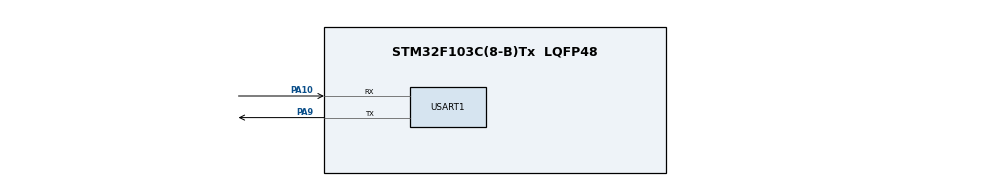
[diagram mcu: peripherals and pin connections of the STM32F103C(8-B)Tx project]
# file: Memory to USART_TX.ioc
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Dma.Request0=USART1_TX
Dma.USART1_TX.0.Direction=DMA_MEMORY_TO_PERIPH
Dma.USART1_TX.0.Instance=DMA1_Channel4
Dma.USART1_TX.0.MemDataAlignment=DMA_MDATAALIGN_BYTE
Dma.USART1_TX.0.MemInc=DMA_MINC_ENABLE
Dma.USART1_TX.0.Mode=DMA_NORMAL
Dma.USART1_TX.0.PeriphDataAlignment=DMA_PDATAALIGN_BYTE
Dma.USART1_TX.0.PeriphInc=DMA_PINC_DISABLE
Dma.USART1_TX.0.Priority=DMA_PRIORITY_HIGH
Mcu.Family=STM32F1
Mcu.Name=STM32F103C(8-B)Tx
Mcu.Package=LQFP48
NVIC.DMA1_Channel4_IRQn=true\:0\:0\:false\:false\:true\:false\:true
NVIC.PriorityGroup=NVIC_PRIORITYGROUP_4
PA10.Mode=Asynchronous
PA10.Signal=USART1_RX
PA13.Mode=Serial_Wire
PA13.Signal=SYS_JTMS-SWDIO
PA14.Mode=Serial_Wire
PA14.Signal=SYS_JTCK-SWCLK
PA9.Mode=Asynchronous
PA9.Signal=USART1_TX
PD0-OSC_IN.Mode=HSE-External-Oscillator
PD0-OSC_IN.Signal=RCC_OSC_IN
PD1-OSC_OUT.Mode=HSE-External-Oscillator
PD1-OSC_OUT.Signal=RCC_OSC_OUT
ProjectManager.HeapSize=0x200
ProjectManager.StackSize=0x400
ProjectManager.TargetToolchain=MDK-ARM V5.27
RCC.APB1Freq_Value=8000000
RCC.APB2Freq_Value=8000000
USART1.VirtualMode=VM_ASYNC
board=custom

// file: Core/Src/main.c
/* USER CODE BEGIN Header */
/**
  ******************************************************************************
  * @file           : main.c
  * @brief          : Main program body
  ******************************************************************************
  * @attention
  *
  * <h2><center>&copy; Copyright (c) 2021 STMicroelectronics.
  * All rights reserved.</center></h2>
  *
  * This software component is licensed by ST under BSD 3-Clause license,
  * the "License"; You may not use this file except in compliance with the
  * License. You may obtain a copy of the License at:
  *                        opensource.org/licenses/BSD-3-Clause
  *
  ******************************************************************************
  */
/* USER CODE END Header */
#include "main.h"

void SystemClock_Config(void);
static void MX_GPIO_Init(void);
static void MX_DMA_Init(void);
static void MX_USART1_UART_Init(void);

int main(void)
{
  /* USER CODE BEGIN 1 */
uint8_t message1[] = "\r\n Hey! This is a test message\r\n";		//Creating a buffer for the message that is to be sent to USART_TX
uint8_t ARRAYSIZE = sizeof(message1);								//Get the size of the buffer
  /* USER CODE END 1 */

  /* MCU Configuration--------------------------------------------------------*/

  /* Reset of all peripherals, Initializes the Flash interface and the Systick. */

  LL_APB2_GRP1_EnableClock(LL_APB2_GRP1_PERIPH_AFIO);
  LL_APB1_GRP1_EnableClock(LL_APB1_GRP1_PERIPH_PWR);

  NVIC_SetPriorityGrouping(NVIC_PRIORITYGROUP_4);

  /* System interrupt init*/

  /** NOJTAG: JTAG-DP Disabled and SW-DP Enabled
  */
  LL_GPIO_AF_Remap_SWJ_NOJTAG();

  /* Configure the system clock */
  SystemClock_Config();

  /* Initialize all configured peripherals */
  MX_GPIO_Init();
  MX_DMA_Init();
  MX_USART1_UART_Init();
  /* USER CODE BEGIN 2 */

	/* configure DMA channel 4 */

  LL_DMA_ConfigAddresses(DMA1,
                         LL_DMA_CHANNEL_4,
                         (uint32_t)message1,
						 LL_USART_DMA_GetRegAddr(USART1),				//Address of the first element of the memory buffer
                         LL_DMA_DIRECTION_MEMORY_TO_PERIPH);

	LL_DMA_SetDataLength(DMA1,
                       LL_DMA_CHANNEL_4,
											 ARRAYSIZE);

    LL_DMA_EnableChannel(DMA1,
                       LL_DMA_CHANNEL_4);

    LL_USART_EnableDMAReq_TX(USART1);									//Enable DMA request
  /* USER CODE END 2 */

  /* Infinite loop */
  while (1)
  {

  }
}

void SystemClock_Config(void)
{
  LL_FLASH_SetLatency(LL_FLASH_LATENCY_0);
  while(LL_FLASH_GetLatency()!= LL_FLASH_LATENCY_0)
  {
  }
  LL_RCC_HSI_SetCalibTrimming(16);
  LL_RCC_HSI_Enable();

   /* Wait till HSI is ready */
  while(LL_RCC_HSI_IsReady() != 1)
  {

  }
  LL_RCC_SetAHBPrescaler(LL_RCC_SYSCLK_DIV_1);
  LL_RCC_SetAPB1Prescaler(LL_RCC_APB1_DIV_1);
  LL_RCC_SetAPB2Prescaler(LL_RCC_APB2_DIV_1);
  LL_RCC_SetSysClkSource(LL_RCC_SYS_CLKSOURCE_HSI);

   /* Wait till System clock is ready */
  while(LL_RCC_GetSysClkSource() != LL_RCC_SYS_CLKSOURCE_STATUS_HSI)
  {

  }
  LL_Init1msTick(8000000);
  LL_SetSystemCoreClock(8000000);
}

static void MX_USART1_UART_Init(void)
{

  LL_USART_InitTypeDef USART_InitStruct = {0};

  LL_GPIO_InitTypeDef GPIO_InitStruct = {0};

  /* Peripheral clock enable */
  LL_APB2_GRP1_EnableClock(LL_APB2_GRP1_PERIPH_USART1);

  LL_APB2_GRP1_EnableClock(LL_APB2_GRP1_PERIPH_GPIOA);
  /**USART1 GPIO Configuration
  PA9   ------> USART1_TX
  PA10   ------> USART1_RX
  */
  GPIO_InitStruct.Pin = LL_GPIO_PIN_9;
  GPIO_InitStruct.Mode = LL_GPIO_MODE_ALTERNATE;
  GPIO_InitStruct.Speed = LL_GPIO_SPEED_FREQ_HIGH;
  GPIO_InitStruct.OutputType = LL_GPIO_OUTPUT_PUSHPULL;
  LL_GPIO_Init(GPIOA, &GPIO_InitStruct);

  GPIO_InitStruct.Pin = LL_GPIO_PIN_10;
  GPIO_InitStruct.Mode = LL_GPIO_MODE_FLOATING;
  LL_GPIO_Init(GPIOA, &GPIO_InitStruct);

  /* USART1 DMA Init */

  /* USART1_TX Init */
  LL_DMA_SetDataTransferDirection(DMA1, LL_DMA_CHANNEL_4, LL_DMA_DIRECTION_MEMORY_TO_PERIPH);

  LL_DMA_SetChannelPriorityLevel(DMA1, LL_DMA_CHANNEL_4, LL_DMA_PRIORITY_HIGH);

  LL_DMA_SetMode(DMA1, LL_DMA_CHANNEL_4, LL_DMA_MODE_NORMAL);

  LL_DMA_SetPeriphIncMode(DMA1, LL_DMA_CHANNEL_4, LL_DMA_PERIPH_NOINCREMENT);

  LL_DMA_SetMemoryIncMode(DMA1, LL_DMA_CHANNEL_4, LL_DMA_MEMORY_INCREMENT);

  LL_DMA_SetPeriphSize(DMA1, LL_DMA_CHANNEL_4, LL_DMA_PDATAALIGN_BYTE);

  LL_DMA_SetMemorySize(DMA1, LL_DMA_CHANNEL_4, LL_DMA_MDATAALIGN_BYTE);

  USART_InitStruct.BaudRate = 115200;
  USART_InitStruct.DataWidth = LL_USART_DATAWIDTH_8B;
  USART_InitStruct.StopBits = LL_USART_STOPBITS_1;
  USART_InitStruct.Parity = LL_USART_PARITY_NONE;
  USART_InitStruct.TransferDirection = LL_USART_DIRECTION_TX_RX;
  USART_InitStruct.HardwareFlowControl = LL_USART_HWCONTROL_NONE;
  USART_InitStruct.OverSampling = LL_USART_OVERSAMPLING_16;
  LL_USART_Init(USART1, &USART_InitStruct);
  LL_USART_ConfigAsyncMode(USART1);
  LL_USART_Enable(USART1);

}

static void MX_DMA_Init(void)
{

  /* Init with LL driver */
  /* DMA controller clock enable */
  LL_AHB1_GRP1_EnableClock(LL_AHB1_GRP1_PERIPH_DMA1);

  /* DMA interrupt init */
  /* DMA1_Channel4_IRQn interrupt configuration */
  NVIC_SetPriority(DMA1_Channel4_IRQn, NVIC_EncodePriority(NVIC_GetPriorityGrouping(),0, 0));
  NVIC_EnableIRQ(DMA1_Channel4_IRQn);

}

static void MX_GPIO_Init(void)
{

  /* GPIO Ports Clock Enable */
  LL_APB2_GRP1_EnableClock(LL_APB2_GRP1_PERIPH_GPIOD);
  LL_APB2_GRP1_EnableClock(LL_APB2_GRP1_PERIPH_GPIOA);

}

void Error_Handler(void)
{
}

/************************ (C) COPYRIGHT STMicroelectronics *****END OF FILE****/
